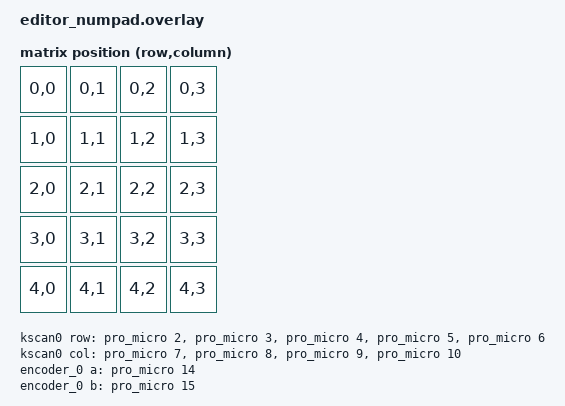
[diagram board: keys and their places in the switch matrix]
/* Generated by ZMK Editor from editor_numpad.editor.json. */

#include <dt-bindings/zmk/matrix_transform.h>
#include <physical_layouts.dtsi>

/ {
    chosen {
        zmk,kscan = &kscan0;
        zmk,physical-layout = &editor_numpad_layout;
    };

    kscan0: kscan {
        compatible = "zmk,kscan-gpio-matrix";
        wakeup-source;
        diode-direction = "row2col";

        row-gpios
            = <&pro_micro  2 GPIO_ACTIVE_HIGH>
            , <&pro_micro  3 GPIO_ACTIVE_HIGH>
            , <&pro_micro  4 GPIO_ACTIVE_HIGH>
            , <&pro_micro  5 GPIO_ACTIVE_HIGH>
            , <&pro_micro  6 GPIO_ACTIVE_HIGH>
            ;

        col-gpios
            = <&pro_micro  7 (GPIO_ACTIVE_HIGH | GPIO_PULL_DOWN)>
            , <&pro_micro  8 (GPIO_ACTIVE_HIGH | GPIO_PULL_DOWN)>
            , <&pro_micro  9 (GPIO_ACTIVE_HIGH | GPIO_PULL_DOWN)>
            , <&pro_micro 10 (GPIO_ACTIVE_HIGH | GPIO_PULL_DOWN)>
            ;
    };

    default_transform: keymap_transform_0 {
        compatible = "zmk,matrix-transform";
        rows = <5>;
        columns = <4>;
        map = <
RC(0,0) RC(0,1) RC(0,2) RC(0,3)
RC(1,0) RC(1,1) RC(1,2) RC(1,3)
RC(2,0) RC(2,1) RC(2,2) RC(2,3)
RC(3,0) RC(3,1) RC(3,2) RC(3,3)
RC(4,0) RC(4,1) RC(4,2) RC(4,3)
        >;
    };

    encoder_0: encoder_0 {
        compatible = "alps,ec11";
        a-gpios = <&pro_micro 14 (GPIO_ACTIVE_HIGH | GPIO_PULL_UP)>;
        b-gpios = <&pro_micro 15 (GPIO_ACTIVE_HIGH | GPIO_PULL_UP)>;
        steps = <80>;
    };

    sensors: sensors {
        compatible = "zmk,keymap-sensors";
        sensors = <&encoder_0>;
        triggers-per-rotation = <20>;
    };

    editor_numpad_layout: editor_numpad_layout {
        compatible = "zmk,physical-layout";
        display-name = "Editor Numpad";
        transform = <&default_transform>;

        keys  //                     w   h    x    y     rot   rx   ry
            = <&key_physical_attrs 100 100    0    0      0    0    0>
            , <&key_physical_attrs 100 100  100    0      0    0    0>
            , <&key_physical_attrs 100 100  200    0      0    0    0>
            , <&key_physical_attrs 100 100  300    0      0    0    0>
            , <&key_physical_attrs 100 100    0  100      0    0    0>
            , <&key_physical_attrs 100 100  100  100      0    0    0>
            , <&key_physical_attrs 100 100  200  100      0    0    0>
            , <&key_physical_attrs 100 100  300  100      0    0    0>
            , <&key_physical_attrs 100 100    0  200      0    0    0>
            , <&key_physical_attrs 100 100  100  200      0    0    0>
            , <&key_physical_attrs 100 100  200  200      0    0    0>
            , <&key_physical_attrs 100 100  300  200      0    0    0>
            , <&key_physical_attrs 100 100    0  300      0    0    0>
            , <&key_physical_attrs 100 100  100  300      0    0    0>
            , <&key_physical_attrs 100 100  200  300      0    0    0>
            , <&key_physical_attrs 100 100  300  300      0    0    0>
            , <&key_physical_attrs 100 100    0  400      0    0    0>
            , <&key_physical_attrs 100 100  100  400      0    0    0>
            , <&key_physical_attrs 100 100  200  400      0    0    0>
            , <&key_physical_attrs 100 100  300  400      0    0    0>
            ;
    };
};
